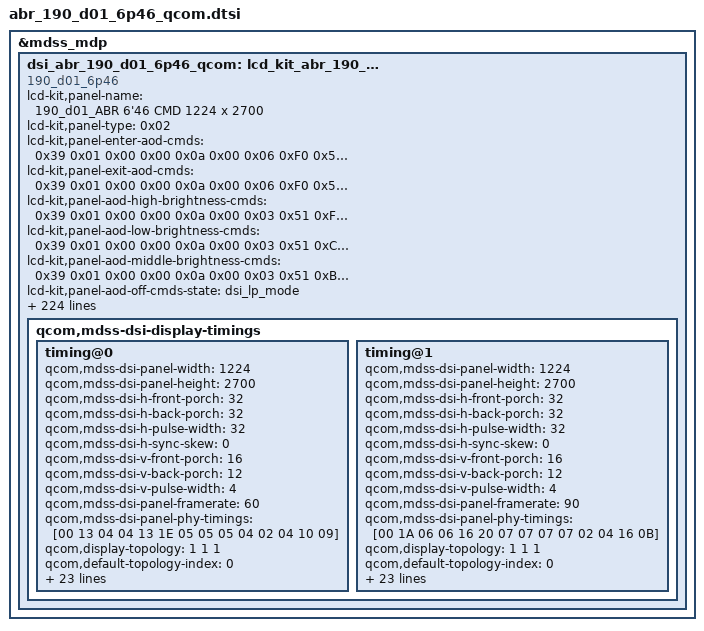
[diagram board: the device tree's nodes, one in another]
/* Copyright (c) 2013, The Linux Foundation. All rights reserved.
 *
 * This program is free software; you can redistribute it and/or modify
 * it under the terms of the GNU General Public License version 2 and
 * only version 2 as published by the Free Software Foundation.
 *
 * This program is distributed in the hope that it will be useful,
 * but WITHOUT ANY WARRANTY; without even the implied warranty of
 * MERCHANTABILITY or FITNESS FOR A PARTICULAR PURPOSE.  See the
 * GNU General Public License for more details.
 */

/*-------------------------------------------------------------------------
 * This file is autogenerated file using gcdb parser. Please do not edit it.
 * Update input XML file to add a new entry or update variable in this file
 * VERSION = 1.1
 *-----------------------------------------------------------------------*/
&mdss_mdp {
	dsi_abr_190_d01_6p46_qcom: lcd_kit_abr_190_d01_6p46_qcom {
		compatible = "190_d01_6p46";
		lcd-kit,panel-name = "190_d01_ABR 6'46 CMD 1224 x 2700";
		lcd-kit,panel-type = <0x02>;
		lcd-kit,panel-enter-aod-cmds = <0x39 0x01 0x00 0x00 0x0a 0x00 0x06 0xF0 0x55 0xAA 0x52 0x08 0x00
			0x15 0x01 0x00 0x00 0x0a 0x00 0x02 0x6F 0x02
			0x15 0x01 0x00 0x00 0x0a 0x00 0x02 0xB5 0x16
			0x39 0x01 0x00 0x00 0x0a 0x00 0x03 0x51 0x00 0x00
			0x05 0x01 0x00 0x00 0x0a 0x00 0x01 0x39>;
		lcd-kit,panel-exit-aod-cmds = <0x39 0x01 0x00 0x00 0x0a 0x00 0x06 0xF0 0x55 0xAA 0x52 0x08 0x00
			0x15 0x01 0x00 0x00 0x0a 0x00 0x02 0x6F 0x0D
			0x15 0x01 0x00 0x00 0x0a 0x00 0x02 0xB5 0x4F
			0x05 0x01 0x00 0x00 0x0a 0x00 0x01 0x38
			0x05 0x01 0x00 0x00 0x0a 0x00 0x01 0x2C>;
		lcd-kit,panel-aod-high-brightness-cmds = <0x39 0x01 0x00 0x00 0x0a 0x00 0x03 0x51 0xFE 0x1F>;
		lcd-kit,panel-aod-low-brightness-cmds = <0x39 0x01 0x00 0x00 0x0a 0x00 0x03 0x51 0xC8 0x02>;
		lcd-kit,panel-aod-middle-brightness-cmds = <0x39 0x01 0x00 0x00 0x0a 0x00 0x03 0x51 0xBE 0x0E>;
		lcd-kit,panel-aod-off-cmds-state = "dsi_lp_mode";
		lcd-kit,pcd-check-reg-cmds = <0x01>;
		lcd-kit,check-reg-on-cmds = <0x06 0x01 0x00 0x00 0x0a 0x00 0x01 0x0a>;
		lcd-kit,check-reg-on-value = <0x9c>;
		lcd-kit,check-aod-reg-on-cmds = <0x06 0x01 0x00 0x00 0x0a 0x00 0x01 0x0a>;
		lcd-kit,check-aod-reg-on-value = <0xdc>;
		lcd-kit,check-reg-off-cmds = <0x06 0x01 0x00 0x00 0x0a 0x00 0x01 0x0a>;
		lcd-kit,check-reg-off-value = <0x08>;
		lcd-kit,check-reg-on-cmds-state = "dsi_lp_mode";
		lcd-kit,check-aod-reg-on-cmds-state = "dsi_lp_mode";
		lcd-kit,check-reg-off-cmds-state = "dsi_lp_mode";
		lcd-kit,pcd-check-reg-value = <0x01>;
		lcd-kit,pcd-errflag-check-support = <0>;
		lcd-kit,checksum-enable-cmds = <0x39 0x01 0x00 0x00 0x64 0x00 0x03 0x9C 0xA5 0xA5>;
		lcd-kit,checksum-enable-cmds-state = "dsi_lp_mode";
		lcd-kit,checksum-disable-cmds = <0x39 0x01 0x00 0x00 0x64 0x00 0x03 0x9C 0xA5 0xA5>;
		lcd-kit,checksum-disable-cmds-state = "dsi_lp_mode";
		lcd-kit,checksum-cmds = <0x39 0x01 0x00 0x00 0x64 0x00 0x03 0x9C 0xA5 0xA5
			0x39 0x01 0x00 0x00 0x64 0x00 0x03 0xFD 0x5A 0x5A
			0x06 0x01 0x00 0x00 0x64 0x00 0x01 0x8F>;
		lcd-kit,checksum-cmds-state = "dsi_lp_mode";
		lcd-kit,checksum-value-size = <1>;
		lcd-kit,checksum-value = <0x00
			0x00
			0x00>;
		lcd-kit,oneside-mode-left = <0x39 0x01 0x00 0x00 0x64 0x00 0x03 0x9C 0xA5 0xA5
			0x39 0x01 0x00 0x00 0x64 0x00 0x03 0xFD 0x5A 0x5A
			0x39 0x01 0x00 0x00 0x00 0x00 0x02 0x9F 0x02
			0x39 0x01 0x00 0x00 0x00 0x00 0x11 0xC1 0x00 0x00 0x00 0x00 0x00 0x00 0x00 0x00 0x00 0x00 0x00 0x00 0x00 0x00 0x00 0x00>;
		lcd-kit,oneside-mode-right = <0x39 0x01 0x00 0x00 0x64 0x00 0x03 0x9C 0xA5 0xA5
			0x39 0x01 0x00 0x00 0x64 0x00 0x03 0xFD 0x5A 0x5A
			0x39 0x01 0x00 0x00 0x00 0x00 0x02 0x9F 0x02
			0x39 0x01 0x00 0x00 0x00 0x00 0x11 0xC2 0x00 0x00 0x00 0x00 0x00 0x00 0x00 0x00 0x00 0x00 0x00 0x00 0x00 0x00 0x00 0x00>;
		lcd-kit,oneside-mode-exit = <0x39 0x01 0x00 0x00 0x64 0x00 0x03 0x9C 0xA5 0xA5
			0x39 0x01 0x00 0x00 0x64 0x00 0x03 0xFD 0x5A 0x5A
			0x39 0x01 0x00 0x00 0x00 0x00 0x02 0x9F 0x02
			0x39 0x01 0x00 0x00 0x00 0x00 0x11 0xC1 0x3D 0x05 0x05 0x23 0x23 0x24 0x24 0x00 0x01 0x01 0x21 0x21 0x22 0x22 0x00 0x00
			0x39 0x01 0x00 0x00 0x00 0x00 0x11 0xC2 0x3D 0x05 0x05 0x23 0x23 0x24 0x24 0x00 0x01 0x01 0x21 0x21 0x22 0x22 0x00 0x00>;
		lcd-kit,color-aod-detect-enter = <0x15 0x01 0x00 0x00 0x00 0x00 0x02 0x90 0x01
			0x39 0x01 0x00 0x00 0x00 0x00 0x03 0x51 0x0F 0xFE>;
		lcd-kit,color-aod-detect-enter-state = "dsi_lp_mode";
		lcd-kit,color-aod-detect-exit = <0x15 0x01 0x00 0x00 0x00 0x00 0x02 0x90 0x00>;
		lcd-kit,color-aod-detect-exit-state = "dsi_lp_mode";
		lcd-kit,hor-line-cmds = <0x29 0x01 0x00 0x00 0x0a 0x00 0x06 0xF0 0x55 0xAA 0x52 0x08 0x00
			0x29 0x01 0x00 0x00 0x0a 0x00 0x02 0x6F 0x06
			0x29 0x01 0x00 0x00 0x0a 0x00 0x02 0xB5 0x4E
			0x29 0x01 0x00 0x00 0x0a 0x00 0x06 0xF0 0x55 0xAA 0x52 0x08 0x01
			0x29 0x01 0x00 0x00 0x0a 0x00 0x03 0xB5 0x01 0xFF
			0x29 0x01 0x00 0x00 0x0a 0x00 0x03 0xB6 0x00 0x00
			0x29 0x01 0x00 0x00 0x0a 0x00 0x02 0xCF 0x00
			0x29 0x01 0x00 0x00 0x0a 0x00 0x06 0xF0 0x55 0xAA 0x52 0x08 0x00
			0x29 0x01 0x00 0x00 0x0a 0x00 0x02 0xC5 0x01
			0x29 0x01 0x00 0x00 0x0a 0x00 0x06 0xF0 0x55 0xAA 0x52 0x08 0x05
			0x29 0x01 0x00 0x00 0x0a 0x00 0x02 0xEC 0x01
			0x29 0x01 0x00 0x00 0x0a 0x00 0x05 0x51 0x0F 0xFF 0x04 0xFF
			0x29 0x01 0x00 0x00 0x0a 0x00 0x02 0x53 0x20
			0x05 0x01 0x00 0x00 0x0a 0x00 0x01 0x35
			0x29 0x01 0x00 0x00 0x0a 0x00 0x05 0x2A 0x00 0x00 0x04 0x37
			0x29 0x01 0x00 0x00 0x0a 0x00 0x05 0x2B 0x00 0x00 0x09 0x23
			0x29 0x01 0x00 0x00 0x0a 0x00 0x06 0xF0 0x55 0xAA 0x52 0x08 0x00
			0x29 0x01 0x00 0x00 0x0a 0x00 0x03 0xBA 0x00 0xF0
			0x29 0x01 0x00 0x00 0x0a 0x00 0x06 0xF0 0x55 0xAA 0x52 0x08 0x06
			0x29 0x01 0x00 0x00 0x0a 0x00 0x06 0xB0 0x34 0x34 0x34 0x34 0x34
			0x29 0x01 0x00 0x00 0x0a 0x00 0x06 0xB1 0x34 0x34 0x11 0x10 0x33
			0x29 0x01 0x00 0x00 0x0a 0x00 0x06 0xB2 0x34 0x0C 0x0D 0x00 0x34
			0x29 0x01 0x00 0x00 0x0a 0x00 0x04 0xB3 0x34 0x34 0x34
			0x29 0x01 0x00 0x00 0x0a 0x00 0x06 0xB6 0x34 0x34 0x34 0x34 0x34
			0x29 0x01 0x00 0x00 0x0a 0x00 0x06 0xB7 0x34 0x34 0x11 0x10 0x33
			0x29 0x01 0x00 0x00 0x0a 0x00 0x06 0xB8 0x34 0x0C 0x0D 0x00 0x34
			0x29 0x01 0x00 0x00 0x0a 0x00 0x04 0xB9 0x34 0x34 0x34
			0x29 0x01 0x00 0x00 0x0a 0x00 0x04 0xBC 0x33 0x33 0x33
			0x29 0x01 0x00 0x00 0x0a 0x00 0x06 0xF0 0x55 0xAA 0x52 0x08 0x01
			0x15 0x01 0x00 0x00 0x0a 0x00 0x02 0xB0 0x0B
			0x15 0x01 0x00 0x00 0x0a 0x00 0x02 0xB1 0x07
			0x29 0x01 0x00 0x00 0x0a 0x00 0x03 0xB3 0x25 0x25
			0x29 0x01 0x00 0x00 0x0a 0x00 0x07 0xB7 0x5A 0x5A 0x5A 0x5A 0x5A 0x5A
			0x29 0x01 0x00 0x00 0x0a 0x00 0x06 0xF0 0x55 0xAA 0x52 0x08 0x01
			0x29 0x01 0x00 0x00 0x0a 0x00 0x03 0xB4 0x25 0x25
			0x29 0x01 0x00 0x00 0x0a 0x00 0x05 0xB8 0x5F 0x5F 0x5F 0x5F
			0x05 0x01 0x00 0x00 0x0a 0x00 0x01 0x11>;
		lcd-kit,hor-line-cmds-state = "dsi_lp_mode";
		lcd-kit,pcd-read-cmds = <0x39 0x01 0x00 0x00 0x64 0x00 0x03 0x9C 0xA5 0xA5
			0x39 0x01 0x00 0x00 0x64 0x00 0x03 0xFD 0x5A 0x5A
			0x15 0x01 0x00 0x00 0x64 0x00 0x02 0x9F 0x04
			0x39 0x01 0x00 0x00 0x64 0x00 0x05 0xC4 0x41 0x10 0x5A 0x00
			0x06 0x01 0x00 0x00 0x64 0x00 0x01 0xD5>;
		lcd-kit,pcd-read-cmds-state  = "dsi_lp_mode";
		lcd-kit,vtc-line-cmds = <0x29 0x01 0x00 0x00 0x0a 0x00 0x06 0xF0 0x55 0xAA 0x52 0x08 0x00
			0x29 0x01 0x00 0x00 0x0a 0x00 0x02 0x6F 0x06
			0x29 0x01 0x00 0x00 0x0a 0x00 0x02 0xB5 0x4E
			0x29 0x01 0x00 0x00 0x0a 0x00 0x06 0xF0 0x55 0xAA 0x52 0x08 0x01
			0x29 0x01 0x00 0x00 0x0a 0x00 0x03 0xB5 0x01 0xFF
			0x29 0x01 0x00 0x00 0x0a 0x00 0x03 0xB6 0x00 0x00
			0x29 0x01 0x00 0x00 0x0a 0x00 0x02 0xCF 0x00
			0x29 0x01 0x00 0x00 0x0a 0x00 0x06 0xF0 0x55 0xAA 0x52 0x08 0x00
			0x29 0x01 0x00 0x00 0x0a 0x00 0x02 0xC5 0x01
			0x29 0x01 0x00 0x00 0x0a 0x00 0x06 0xF0 0x55 0xAA 0x52 0x08 0x05
			0x29 0x01 0x00 0x00 0x0a 0x00 0x02 0xEC 0x01
			0x29 0x01 0x00 0x00 0x0a 0x00 0x02 0x53 0x20
			0x05 0x01 0x00 0x00 0x0a 0x00 0x01 0x35
			0x29 0x01 0x00 0x00 0x0a 0x00 0x05 0x2A 0x00 0x00 0x04 0x37
			0x29 0x01 0x00 0x00 0x0a 0x00 0x05 0x2B 0x00 0x00 0x09 0x23
			0x29 0x01 0x00 0x00 0x0a 0x00 0x06 0xF0 0x55 0xAA 0x52 0x08 0x00
			0x29 0x01 0x00 0x00 0x0a 0x00 0x03 0xBA 0x01 0xE0
			0x29 0x01 0x00 0x00 0x0a 0x00 0x06 0xF0 0x55 0xAA 0x52 0x08 0x06
			0x29 0x01 0x00 0x00 0x0a 0x00 0x06 0xB0 0x34 0x34 0x34 0x34 0x34
			0x29 0x01 0x00 0x00 0x0a 0x00 0x06 0xB1 0x34 0x34 0x11 0x10 0x33
			0x29 0x01 0x00 0x00 0x0a 0x00 0x06 0xB2 0x34 0x33 0x33 0x00 0x33
			0x29 0x01 0x00 0x00 0x0a 0x00 0x04 0xB3 0x33 0x33 0x33
			0x29 0x01 0x00 0x00 0x0a 0x00 0x06 0xB6 0x34 0x34 0x34 0x34 0x34
			0x29 0x01 0x00 0x00 0x0a 0x00 0x06 0xB7 0x34 0x34 0x11 0x10 0x33
			0x29 0x01 0x00 0x00 0x0a 0x00 0x06 0xB8 0x34 0x33 0x33 0x00 0x33
			0x29 0x01 0x00 0x00 0x0a 0x00 0x04 0xB9 0x33 0x33 0x33
			0x29 0x01 0x00 0x00 0x0a 0x00 0x04 0xBC 0x33 0x33 0x33
			0x29 0x01 0x00 0x00 0x0a 0x00 0x06 0xF0 0x55 0xAA 0x52 0x08 0x07
			0x29 0x01 0x00 0x00 0x0a 0x00 0x02 0xB0 0x00
			0x05 0x01 0x00 0x00 0xc8 0x01 0x01 0x11
			0x05 0x01 0x00 0x00 0x0a 0x00 0x01 0x29
			0x29 0x01 0x00 0x00 0x0a 0x00 0x06 0xF0 0x55 0xAA 0x52 0x08 0x02
			0x29 0x01 0x00 0x00 0x0a 0x00 0x02 0xBF 0x00
			0x29 0x01 0x00 0x00 0x0a 0x00 0x19 0xB0 0x00 0x00 0x0F 0xFF 0x0F 0xFF 0x0F 0xFF 0x0F 0xFF 0x0F 0xFF 0x0F 0xFF 0x0F 0xFF 0x0F 0xFF 0x0F 0xFF 0x0F 0xFF 0x0F 0xFF
			0x29 0x01 0x00 0x00 0x0a 0x00 0x19 0xB1 0x0F 0xFF 0x0F 0xFF 0x0F 0xFF 0x0F 0xFF 0x0F 0xFF 0x0F 0xFF 0x0F 0xFF 0x0F 0xFF 0x0F 0xFF 0x0F 0xFF 0x0F 0xFF 0x0F 0xFF
			0x29 0x01 0x00 0x00 0x0a 0x00 0x17 0xB2 0x0F 0xFF 0x0F 0xFF 0x0F 0xFF 0x0F 0xFF 0x0F 0xFF 0x0F 0xFF 0x0F 0xFF 0x0F 0xFF 0x0F 0xFF 0x0F 0xFF 0x0F 0xFF
			0x29 0x01 0x00 0x00 0x0a 0x00 0x19 0xB3 0x00 0x00 0x0F 0xFF 0x0F 0xFF 0x0F 0xFF 0x0F 0xFF 0x0F 0xFF 0x0F 0xFF 0x0F 0xFF 0x0F 0xFF 0x0F 0xFF 0x0F 0xFF 0x0F 0xFF
			0x29 0x01 0x00 0x00 0x0a 0x00 0x19 0xB4 0x0F 0xFF 0x0F 0xFF 0x0F 0xFF 0x0F 0xFF 0x0F 0xFF 0x0F 0xFF 0x0F 0xFF 0x0F 0xFF 0x0F 0xFF 0x0F 0xFF 0x0F 0xFF 0x0F 0xFF
			0x29 0x01 0x00 0x00 0x0a 0x00 0x17 0xB5 0x0F 0xFF 0x0F 0xFF 0x0F 0xFF 0x0F 0xFF 0x0F 0xFF 0x0F 0xFF 0x0F 0xFF 0x0F 0xFF 0x0F 0xFF 0x0F 0xFF 0x0F 0xFF
			0x29 0x01 0x00 0x00 0x0a 0x00 0x19 0xB6 0x00 0x00 0x0F 0xFF 0x0F 0xFF 0x0F 0xFF 0x0F 0xFF 0x0F 0xFF 0x0F 0xFF 0x0F 0xFF 0x0F 0xFF 0x0F 0xFF 0x0F 0xFF 0x0F 0xFF
			0x29 0x01 0x00 0x00 0x0a 0x00 0x19 0xB7 0x0F 0xFF 0x0F 0xFF 0x0F 0xFF 0x0F 0xFF 0x0F 0xFF 0x0F 0xFF 0x0F 0xFF 0x0F 0xFF 0x0F 0xFF 0x0F 0xFF 0x0F 0xFF 0x0F 0xFF
			0x29 0x01 0x00 0x00 0x0a 0x00 0x17 0xB8 0x0F 0xFF 0x0F 0xFF 0x0F 0xFF 0x0F 0xFF 0x0F 0xFF 0x0F 0xFF 0x0F 0xFF 0x0F 0xFF 0x0F 0xFF 0x0F 0xFF 0x0F 0xFF
			0x29 0x01 0x00 0x00 0x0a 0x00 0x06 0xF0 0x55 0xAA 0x52 0x08 0x02
			0x29 0x01 0x00 0x00 0x0a 0x00 0x05 0x51 0x00 0x00 0x04 0xFF>;
		lcd-kit,vtc-line-cmds-state  = "dsi_lp_mode";
		lcd-kit,ddic-lv-det-enter1-cmds = <0x39 0x01 0x00 0x00 0x0a 0x00 0x06 0xF0 0x55 0xAA 0x52 0x08 0x01
			0x39 0x01 0x00 0x00 0x14 0x01 0x05 0xC7 0x60 0x74 0xC4 0x1F>;
		lcd-kit,ddic-lv-det-enter1-cmds-state  = "dsi_lp_mode";
		lcd-kit,ddic-lv-det-enter2-cmds = <0x39 0x01 0x00 0x00 0x0a 0x00 0x06 0xF0 0x55 0xAA 0x52 0x08 0x01
			0x39 0x01 0x00 0x00 0x14 0x01 0x05 0xC7 0x60 0x74 0xC4 0x1F>;
		lcd-kit,ddic-lv-det-enter2-cmds-state  = "dsi_lp_mode";
		lcd-kit,ddic-lv-det-enter3-cmds = <0x39 0x01 0x00 0x00 0x0a 0x00 0x06 0xF0 0x55 0xAA 0x52 0x08 0x01
			0x39 0x01 0x00 0x00 0x14 0x01 0x05 0xC7 0x60 0x74 0xC4 0x1F>;
		lcd-kit,ddic-lv-det-enter3-cmds-state  = "dsi_lp_mode";
		lcd-kit,ddic-lv-det-enter4-cmds = <0x39 0x01 0x00 0x00 0x0a 0x00 0x06 0xF0 0x55 0xAA 0x52 0x08 0x01
			0x39 0x01 0x00 0x00 0x14 0x01 0x05 0xC7 0x60 0x74 0xC4 0x1F>;
		lcd-kit,ddic-lv-det-enter4-cmds-state  = "dsi_lp_mode";
		lcd-kit,ddic-lv-det-rd1-cmds = <0x06 0x01 0x00 0x00 0x0a 0x00 0x01 0x0a>;
		lcd-kit,ddic-lv-det-rd1-cmds-state  = "dsi_lp_mode";
		lcd-kit,ddic-lv-det-rd2-cmds = <0x06 0x01 0x00 0x00 0x0a 0x00 0x01 0x0a>;
		lcd-kit,ddic-lv-det-rd2-cmds-state  = "dsi_lp_mode";
		lcd-kit,ddic-lv-det-rd3-cmds = <0x06 0x01 0x00 0x00 0x0a 0x00 0x01 0x0a>;
		lcd-kit,ddic-lv-det-rd3-cmds-state  = "dsi_lp_mode";
		lcd-kit,ddic-lv-det-rd4-cmds = <0x06 0x01 0x00 0x00 0x0a 0x00 0x01 0x0a>;
		lcd-kit,ddic-lv-det-rd4-cmds-state  = "dsi_lp_mode";
		lcd-kit,ddic-lv-det-value1 = <0x9c>;
		lcd-kit,ddic-lv-det-value2 = <0x9c>;
		lcd-kit,ddic-lv-det-value3 = <0x9c>;
		lcd-kit,ddic-lv-det-value4 = <0x9c>;
		lcd-kit,ap-aod-support = <1>;
		lcd-kit,left-time-to-te-us = <6000>;
		lcd-kit,right-time-to-te-us = <14000>;
		lcd-kit,te-interval-time-us = <16667>;
		lcd-kit,oneside-mode-support = <1>;
		lcd-kit,color-aod-detect-support = <1>;
		lcd-kit,elvdd-detect-support = <0>;
		lcd-kit,elvdd-detect-type = <2>;
		lcd-kit,elvdd-detect-value = <1>;
		lcd-kit,elvdd-delay = <50>;
		lcd-kit,elvdd-detect-gpio = <33>;
		lcd-kit,check-reg-on-support = <0>;
		lcd-kit,check-reg-on-support-dsm-report = <0>;
		lcd-kit,check-aod-reg-on-support = <0>;
		lcd-kit,check-aod-reg-on-support-dsm-report = <0>;
		lcd-kit,check-reg-off-support = <0>;
		lcd-kit,check-reg-off-support-dsm-report = <0>;
		lcd-kit,checksum-support = <1>;
		lcd-kit,pcd-cmds-support = <1>;
		lcd-kit,pcd-check-reg-value-compare-mode = <2>;
		lcd-kit,exp-pcd-mask = <0xff>;
		lcd-kit,vtc-line-support = <0>;
		lcd-kit,ddic-lv-det-support = <0>;
		lcd-kit,hor-line-support = <0>;
		lcd-kit,hor-line-duration = <600>;
		qcom,mdss-dsi-panel-type = "dsi_cmd_mode";
		qcom,mdss-pan-physical-width-dimension = <69>;
		qcom,mdss-pan-physical-height-dimension = <154>;
		qcom,dsi-ctrl-num = <0>;
		qcom,dsi-phy-num = <0>;
		qcom,panel-supply-entries = <&dsi_panel_pwr_supply>;
		qcom,mdss-dsi-virtual-channel-id = <0>;
		qcom,mdss-dsi-h-sync-pulse = <0>;
		qcom,mdss-dsi-bllp-eof-power-mode;
		qcom,mdss-dsi-bllp-power-mode;
		qcom,mdss-dsi-dma-schedule-line = <1>;
		qcom,mdss-dsi-bpp = <24>;
		qcom,mdss-dsi-color-order = "rgb_swap_rgb";
		qcom,mdss-dsi-underflow-color = <0xff>;
		qcom,mdss-dsi-border-color = <0>;
		qcom,mdss-dsi-traffic-mode = "burst_mode";
		qcom,mdss-dsi-lane-map = "lane_map_0123";
		qcom,mdss-dsi-lane-0-state;
		qcom,mdss-dsi-lane-1-state;
		qcom,mdss-dsi-lane-2-state;
		qcom,mdss-dsi-lane-3-state;
		qcom,mdss-dsi-mdp-trigger = "none";
		qcom,mdss-dsi-dma-trigger = "trigger_sw";
		qcom,mdss-dsi-te-pin-select = <1>;
		qcom,mdss-dsi-wr-mem-start = <0x2c>;
		qcom,mdss-dsi-wr-mem-continue = <0x3c>;
		qcom,mdss-dsi-te-dcs-command = <1>;
		qcom,mdss-dsi-te-check-enable;
		qcom,mdss-dsi-te-using-te-pin;
		qcom,dsi-panel-gpio-address = <0x0F100000 0x1000>;
		qcom,dsi-panel-gpio-pins = <12 24 82>;
		qcom,dsi-panel-gpio-names = "reg-gpio", "reset-gpio", "platform-te-gpio";
		qcom,mdss-dsi-t-clk-post = <0>;
		qcom,mdss-dsi-t-clk-pre = <0>;
		qcom,dsi-select-clocks = "mux_byte_clk0", "mux_pixel_clk0";
		qcom,mdss-dsi-stream = <0>;
		qcom,mdss-dsi-lp11-init;
		qcom,sublinks-count = <2>;
		qcom,lanes-per-sublink = <2>;
		qcom,mdss-dsi-panel-hdr-color-primaries = <14500 15500 32000 17000 15500 30000 8000 3000>;
		qcom,mdss-dsi-panel-peak-brightness = <4200000>;
		qcom,mdss-dsi-panel-blackness-level = <3230>;
		qcom,dynamic-mode-switch-enabled;
		qcom,dynamic-mode-switch-type = "dynamic-resolution-switch-immediate";
		qcom,mdss-dsi-bl-pmic-control-type = "bl_ctrl_dcs";
		qcom,mdss-dsi-bl-min-level = <1>;
		qcom,mdss-dsi-bl-max-level = <8191>;
		qcom,esd-check-enabled;
		qcom,mdss-dsi-panel-status-command = [06 01 00 00 00 00 01 0A
			06 01 00 00 00 00 01 8F];
		qcom,mdss-dsi-panel-status-command-state = "dsi_lp_mode";
		qcom,mdss-dsi-panel-status-check-mode = "reg_read";
		qcom,mdss-dsi-panel-status-read-length = <1 1>;
		qcom,mdss-dsi-panel-status-value = <0x9C>,<0x00>;
		lcd-kit,power-on-stage = <2 1 1
				9 1 1
				3 1 1
				1 1 10
				5 1 10
				7 1 0
				6 1 0
				8 1 0>;
		lcd-kit,lp-on-stage = <0 0 0>;
		lcd-kit,lp-off-stage = <0 0 0>;
		lcd-kit,power-off-stage = <7 0 0
				6 0 0
				8 0 0
				5 0 1
				1 0 1
				3 0 1
				9 0 1
				2 0 1>;
		lcd-kit,only-power-off-stage = <0 0 0>;
		lcd-kit,pt-support = <1>;
		lcd-kit,panel-on-always-reset = <0>;
		lcd-kit,lcd-vci = <1 13 3000000 3000000 3000000 10000 80>;
		lcd-kit,lcd-iovcc = <1 12 1800000 1800000 1800000 60700 80>;
		lcd-kit,lcd-vdd = <2 34 1200000>;
		lcd-kit,lcd-vsp = <1 1 1200000 1200000 1200000 60700 80>;
		lcd-kit,lcd-reset = <2 24 0>;
		lcd-kit,lcd-vci-name = "vdd";
		lcd-kit,lcd-iovcc-name = "vddio";
		lcd-kit,lcd-vsp-name = "ddic";
		lcd-kit,project-id-support = <0>;
		lcd-kit,default-project-id = "G240A7130";
		lcd-kit,sn-code-support = <1>;
		lcd-kit,oem-info-support = <1>;
		lcd-kit,oem-barcode-2d-support = <1>;
		lcd-kit,oem-barcode-2d-num-offset = <0>;
		lcd-kit,barcode-2d-cmds = <0x14 0x01 0x00 0x00 0x0a 0x00 0x13 0xB1 0x00 0x00 0x00 0x00 0x00 0x00 0x00 0x00 0x00 0x00 0x00 0x00 0x00 0x00 0x00 0x00 0x00 0x00
			0x06 0x01 0x00 0x00 0x0a 0x00 0x01 0x85
			0x06 0x01 0x00 0x00 0x0a 0x00 0x01 0xDA>;
		lcd-kit,barcode-2d-cmds-state = "dsi_lp_mode";
		lcd-kit,panel-getblmaxnit-type = <0>;
		lcd-kit,panel-blmaxnit-min-value = <400>;
		lcd-kit,inversion-support = <0>;
		lcd-kit,panel-gpio-offset = <308>;
		lcd-kit,finger-unlock-state-support = <0>;
		lcd-kit,panel-bl-max-nit = <450>;
		lcd-kit,panel-bl-min = <4>;
		lcd-kit,panel-bl-max = <8191>;
		lcd-kit,panel-bl-def = <4095>;
		lcd-kit,check-reg-support = <0>;
		lcd-kit,thp-proximity-support = <0>;
		lcd-kit,proximity-reset-delay-min = <65>;
		lcd-kit,backlight-cmds = <0x39 0x01 0x00 0x00 0x00 0x00 0x03 0x51 0x00 0x00>;
		lcd-kit,backlight-cmds-state = "dsi_lp_mode";
		lcd-kit,backlight-order = <1>;
		lcd-kit,backlight-need-sync = <0>;
		lcd-kit,fps-support = <1>;
		lcd-kit,default-fps = <60>;
		lcd-kit,panel-support-fps-list = <60 90>;
		qcom,mdss-dsi-display-timings {
			timing@0 {
				qcom,mdss-dsi-panel-width = <1224>;
				qcom,mdss-dsi-panel-height = <2700>;
				qcom,mdss-dsi-h-front-porch = <32>;
				qcom,mdss-dsi-h-back-porch = <32>;
				qcom,mdss-dsi-h-pulse-width = <32>;
				qcom,mdss-dsi-h-sync-skew = <0>;
				qcom,mdss-dsi-v-front-porch = <16>;
				qcom,mdss-dsi-v-back-porch = <12>;
				qcom,mdss-dsi-v-pulse-width = <4>;
				qcom,mdss-dsi-panel-framerate = <60>;
				qcom,mdss-dsi-panel-phy-timings= [00 13 04 04 13 1E 05
			05 05 04 02 04 10 09];
				qcom,display-topology  = <1 1 1>;
				qcom,default-topology-index  = <0>;
				qcom,mdss-dsi-on-command = [39 01 00 00 00 00 03 9C A5 A5
			39 01 00 00 00 00 03 FD 5A 5A
			15 01 00 00 00 00 02 48 00
			39 01 00 00 00 00 03 51 00 00
			15 01 00 00 00 00 02 53 E0
			05 01 00 00 00 00 01 35
			05 01 00 00 78 00 01 11
			15 01 00 00 00 00 02 9F 04
			39 01 00 00 00 00 05 C8 4E 4E 54 54
			39 01 00 00 00 00 15 C9 16 23 24 25 26 27 27 27 27 27 2A 2A 2A 2A 1F 1F 1F 1F 1F 1F
			39 01 00 00 00 00 15 CA 16 23 24 25 26 27 27 27 27 27 2A 2A 2A 2A 1F 1F 1F 1F 1F 1F
			39 01 00 00 00 00 15 CB 16 23 24 25 26 27 27 27 27 27 2A 2A 2A 2A 1F 1F 1F 1F 1F 1F
			39 01 00 00 00 00 15 CC 16 23 24 25 26 27 27 27 27 27 2A 2A 2A 2A 1F 1F 1F 1F 1F 1F
			05 01 00 00 00 00 01 29];
				qcom,mdss-dsi-on-command-state = "dsi_lp_mode";
				qcom,mdss-dsi-off-command = [05 01 00 00 14 00 01 28
			05 01 00 00 78 00 01 10];
				qcom,mdss-dsi-off-command-state = "dsi_lp_mode";
				qcom,compression-mode = "dsc";
				qcom,mdss-dsc-slice-height = <60>;
				qcom,mdss-dsc-slice-width = <1224>;
				qcom,mdss-dsc-slice-per-pkt = <1>;
				qcom,mdss-dsc-bit-per-component = <8>;
				qcom,mdss-dsc-bit-per-pixel = <8>;
				qcom,mdss-dsc-block-prediction-enable;
				qcom,mdss-dsi-timing-switch-command = [15 01 00 00 00 00 02 48 00];
				qcom,mdss-dsi-timing-switch-command-state = "dsi_lp_mode";
				qcom,mdss-dsi-lp1-command = [15 01 00 00 00 00 02 90 01];
				qcom,mdss-dsi-lp1-command-state = "dsi_lp_mode";
				qcom,mdss-dsi-nolp-command = [15 01 00 00 00 00 02 90 00
		15 01 00 00 00 00 02 48 00];
				qcom,mdss-dsi-nolp-command-state = "dsi_lp_mode";
			};
			timing@1 {
				qcom,mdss-dsi-panel-width = <1224>;
				qcom,mdss-dsi-panel-height = <2700>;
				qcom,mdss-dsi-h-front-porch = <32>;
				qcom,mdss-dsi-h-back-porch = <32>;
				qcom,mdss-dsi-h-pulse-width = <32>;
				qcom,mdss-dsi-h-sync-skew = <0>;
				qcom,mdss-dsi-v-front-porch = <16>;
				qcom,mdss-dsi-v-back-porch = <12>;
				qcom,mdss-dsi-v-pulse-width = <4>;
				qcom,mdss-dsi-panel-framerate = <90>;
				qcom,mdss-dsi-panel-phy-timings= [00 1A 06 06 16 20 07
			07 07 07 02 04 16 0B];
				qcom,display-topology  = <1 1 1>;
				qcom,default-topology-index  = <0>;
				qcom,mdss-dsi-on-command = [39 01 00 00 00 00 03 9C A5 A5
			39 01 00 00 00 00 03 FD 5A 5A
			15 01 00 00 00 00 02 48 00
			39 01 00 00 00 00 03 51 00 00
			15 01 00 00 00 00 02 53 E0
			05 01 00 00 00 00 01 35
			05 01 00 00 78 00 01 11
			15 01 00 00 00 00 02 9F 04
			39 01 00 00 00 00 05 C8 4E 4E 54 54
			39 01 00 00 00 00 15 C9 16 23 24 25 26 27 27 27 27 27 2A 2A 2A 2A 1F 1F 1F 1F 1F 1F
			39 01 00 00 00 00 15 CA 16 23 24 25 26 27 27 27 27 27 2A 2A 2A 2A 1F 1F 1F 1F 1F 1F
			39 01 00 00 00 00 15 CB 16 23 24 25 26 27 27 27 27 27 2A 2A 2A 2A 1F 1F 1F 1F 1F 1F
			39 01 00 00 00 00 15 CC 16 23 24 25 26 27 27 27 27 27 2A 2A 2A 2A 1F 1F 1F 1F 1F 1F
			15 01 00 00 00 00 02 48 10
			05 01 00 00 00 00 01 29];
				qcom,mdss-dsi-on-command-state = "dsi_lp_mode";
				qcom,mdss-dsi-off-command = [05 01 00 00 14 00 01 28
			05 01 00 00 78 00 01 10];
				qcom,mdss-dsi-off-command-state = "dsi_lp_mode";
				qcom,compression-mode = "dsc";
				qcom,mdss-dsc-slice-height = <60>;
				qcom,mdss-dsc-slice-width = <1224>;
				qcom,mdss-dsc-slice-per-pkt = <1>;
				qcom,mdss-dsc-bit-per-component = <8>;
				qcom,mdss-dsc-bit-per-pixel = <8>;
				qcom,mdss-dsc-block-prediction-enable;
				qcom,mdss-dsi-timing-switch-command = [15 01 00 00 00 00 02 48 10];
				qcom,mdss-dsi-timing-switch-command-state = "dsi_lp_mode";
				qcom,mdss-dsi-lp1-command = [15 01 00 00 00 00 02 90 01];
				qcom,mdss-dsi-lp1-command-state = "dsi_lp_mode";
				qcom,mdss-dsi-nolp-command = [15 01 00 00 00 00 02 90 00
		15 01 00 00 00 00 02 48 10];
				qcom,mdss-dsi-nolp-command-state = "dsi_lp_mode";
			};
		};
    };
};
